# $root: IP-XACT component
VLNV example.org:mylibrary:$root:1.0

## Address spaces and blocks
cr_mmap.cr: base 'h0, range 'h1a08, width 64

## Registers
Registers are 64-bit, read-write, reset 0x0 unless marked. A register's access mark holds for its fields unless they carry their own. Offsets are from the block's base; lines under a group give offsets from that group; [hi:lo] are bit positions; {n}, {i} and the like mark numbered series; 'fields as' and 'values as' point back to an identical list; <NAME> marks a mode.

## cr_mmap.cr
Base 0x00000000
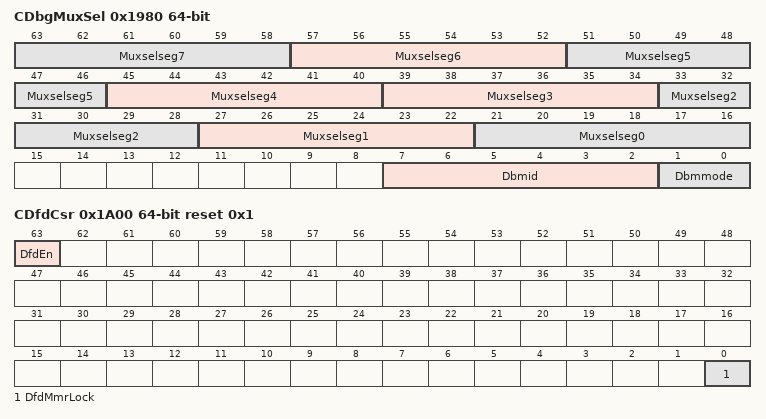
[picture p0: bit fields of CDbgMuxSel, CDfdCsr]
0x1980 CDbgMuxSel
  [6n+21:6n+16] Muxselseg{n} (n=4..7)
  [39:34] Muxselseg3 — Mux Select Bits for Lane 3. Split debug bus into 16 bit segments. Seg0 = debug bus [15:0], Seg1 = debug bus[31:16],.... If all bits are 0, Lane3= Seg3, if bit[0] = 1, Lane3 = Seg4, if bit[1] =1, Lane3 = Seg5,...
  [33:28] Muxselseg2 — Mux Select Bits for Lane 2. Split debug bus into 16 bit segments. Seg0 = debug bus [15:0], Seg1 = debug bus[31:16],.... If all bits are 0, Lane2= Seg2, if bit[0] = 1, Lane2 = Seg4, if bit[1] =1, Lane2 = Seg5,...
  [27:22] Muxselseg1 — Mux Select Bits for Lane 1. Split debug bus into 16 bit segments. Seg0 = debug bus [15:0], Seg1 = debug bus[31:16],.... If all bits are 0, Lane1= Seg1, if bit[0] = 1, Lane1 = Seg4, if bit[1] =1, Lane1 = Seg5,...
  [21:16] Muxselseg0 — Mux Select Bits for Lane 0. Split debug bus into 16 bit segments. Seg0 = debug bus [15:0], Seg1 = debug bus[31:16],.... If all bits are 0, Lane0 = Seg0, if bit[0] = 1, Lane0 = Seg4, if bit[1] =1, Lane0 = Seg5,...
  [7:2] Dbmid — Unique DBM ID of the DBM instance
  [1:0] Dbmmode — Mode selection, 0: DBM off, 1: Normal debug mode, 2: DBM ID output mode, 3: Toggle Mode
0x1A00 CDfdCsr access per field reset 0x1
  [63] DfdEn rw, [0] DfdMmrLock rw
